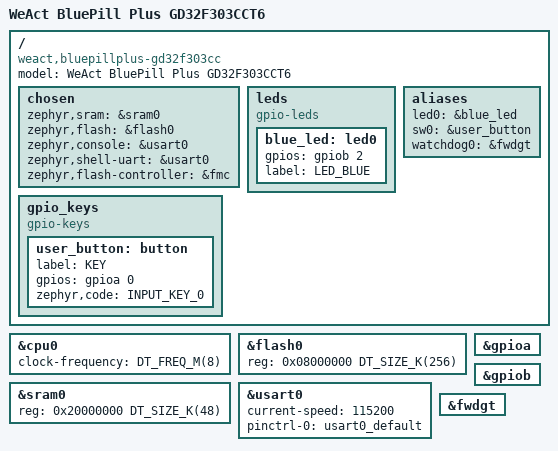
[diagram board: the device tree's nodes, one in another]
/*
 * Copyright The Zephyr Project Contributors
 * SPDX-License-Identifier: Apache-2.0
 */

/dts-v1/;

#include <gd/gd32f403/gd32f403zet6.dtsi>
#include <zephyr/dt-bindings/input/input-event-codes.h>
#include "bluepillplus_gd32f303cc-pinctrl.dtsi"

/ {
	model = "WeAct BluePill Plus GD32F303CCT6";
	compatible = "weact,bluepillplus-gd32f303cc";

	chosen {
		zephyr,sram = &sram0;
		zephyr,flash = &flash0;
		zephyr,console = &usart0;
		zephyr,shell-uart = &usart0;
		zephyr,flash-controller = &fmc;
	};

	leds {
		compatible = "gpio-leds";

		blue_led: led0 {
			gpios = <&gpiob 2 GPIO_ACTIVE_HIGH>;
			label = "LED_BLUE";
		};
	};

	gpio_keys {
		compatible = "gpio-keys";

		user_button: button {
			label = "KEY";
			gpios = <&gpioa 0 (GPIO_ACTIVE_HIGH | GPIO_PULL_DOWN)>;
			zephyr,code = <INPUT_KEY_0>;
		};
	};

	aliases {
		led0 = &blue_led;
		sw0 = &user_button;
		watchdog0 = &fwdgt;
	};
};

/*
 * GD32F303CCT6 memory map (datasheet); SoC DTS is F403 stand-in.
 * Run from 8 MHz HXTAL until a real F30x clock driver exists (PLL baud issues).
 */
&cpu0 {
	clock-frequency = <DT_FREQ_M(8)>;
};

&flash0 {
	reg = <0x08000000 DT_SIZE_K(256)>;
	ranges = <0x0 0x08000000 DT_SIZE_K(256)>;
};

&sram0 {
	reg = <0x20000000 DT_SIZE_K(48)>;
};

&gpioa {
	status = "okay";
};

&gpiob {
	status = "okay";
};

&usart0 {
	current-speed = <115200>;
	pinctrl-0 = <&usart0_default>;
	pinctrl-names = "default";
	status = "okay";
};

&fwdgt {
	status = "okay";
};
